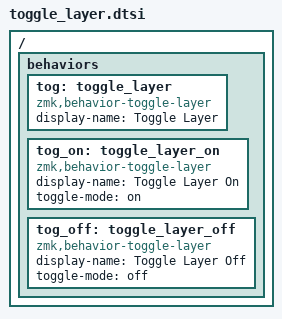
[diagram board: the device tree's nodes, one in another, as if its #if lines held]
/*
 * Copyright (c) 2020 The ZMK Contributors
 *
 * SPDX-License-Identifier: MIT
 */

#include <dt-bindings/zmk/behaviors.h>

/ {
    behaviors {
#if ZMK_BEHAVIOR_OMIT(TOG)
        /omit-if-no-ref/
#endif
        tog: toggle_layer {
            compatible = "zmk,behavior-toggle-layer";
            #binding-cells = <1>;
            display-name = "Toggle Layer";
        };

#if ZMK_BEHAVIOR_OMIT(TOG_ON)
        /omit-if-no-ref/
#endif
        tog_on: toggle_layer_on {
            compatible = "zmk,behavior-toggle-layer";
            #binding-cells = <1>;
            display-name = "Toggle Layer On";
            toggle-mode = "on";
        };

#if ZMK_BEHAVIOR_OMIT(TOG_OFF)
        /omit-if-no-ref/
#endif
        tog_off: toggle_layer_off {
            compatible = "zmk,behavior-toggle-layer";
            #binding-cells = <1>;
            display-name = "Toggle Layer Off";
            toggle-mode = "off";
        };
    };
};
